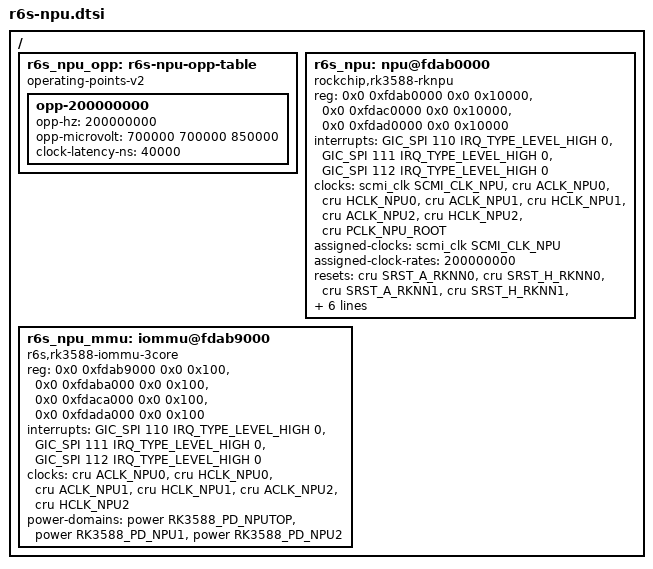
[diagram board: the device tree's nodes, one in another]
// SPDX-License-Identifier: (GPL-2.0+ OR MIT)
/* Modified 2026-10-11 for the R6S port; see docs/PORTING.md. */
/* R6S three-core mainline port. Register/IRQ/reset data are vendor0.9.8
 * and upstream v6.18 all three cores; initial SCMI rate is the upstream 200MHz.
 * The 700mV value is the vendor's ordinary 300/400MHz default voltage,
 * used here at the lower assigned rate. Hardware bring-up has been observed; full qualification remains incomplete. */
/ {
 r6s_npu_opp: r6s-npu-opp-table {
  compatible = "operating-points-v2";
  opp-200000000 {
   opp-hz = /bits/ 64 <200000000>;
   opp-microvolt = <700000 700000 850000>;
   clock-latency-ns = <40000>;
  };
 };
 r6s_npu: npu@fdab0000 {
  compatible = "rockchip,rk3588-rknpu";
  reg = <0x0 0xfdab0000 0x0 0x10000>,
        <0x0 0xfdac0000 0x0 0x10000>,
        <0x0 0xfdad0000 0x0 0x10000>;
  interrupts = <GIC_SPI 110 IRQ_TYPE_LEVEL_HIGH 0>,
               <GIC_SPI 111 IRQ_TYPE_LEVEL_HIGH 0>,
               <GIC_SPI 112 IRQ_TYPE_LEVEL_HIGH 0>;
  interrupt-names = "npu0_irq", "npu1_irq", "npu2_irq";
  clocks = <&scmi_clk SCMI_CLK_NPU>, <&cru ACLK_NPU0>,
           <&cru HCLK_NPU0>, <&cru ACLK_NPU1>, <&cru HCLK_NPU1>,
           <&cru ACLK_NPU2>, <&cru HCLK_NPU2>, <&cru PCLK_NPU_ROOT>;
  clock-names = "clk_npu", "aclk0", "hclk0", "aclk1", "hclk1", "aclk2", "hclk2", "pclk";
  assigned-clocks = <&scmi_clk SCMI_CLK_NPU>;
  assigned-clock-rates = <200000000>;
  resets = <&cru SRST_A_RKNN0>, <&cru SRST_H_RKNN0>,
           <&cru SRST_A_RKNN1>, <&cru SRST_H_RKNN1>,
           <&cru SRST_A_RKNN2>, <&cru SRST_H_RKNN2>;
  reset-names = "srst_a0", "srst_h0", "srst_a1", "srst_h1", "srst_a2", "srst_h2";
  power-domains = <&power RK3588_PD_NPUTOP>,
                  <&power RK3588_PD_NPU1>, <&power RK3588_PD_NPU2>;
  power-domain-names = "npu0", "npu1", "npu2";
  operating-points-v2 = <&r6s_npu_opp>;
  rknpu-supply = <&vdd_npu_s0>;
  iommus = <&r6s_npu_mmu>;
  status = "okay";
 };
 r6s_npu_mmu: iommu@fdab9000 {
  compatible = "r6s,rk3588-iommu-3core";
  reg = <0x0 0xfdab9000 0x0 0x100>,
        <0x0 0xfdaba000 0x0 0x100>,
        <0x0 0xfdaca000 0x0 0x100>,
        <0x0 0xfdada000 0x0 0x100>;
  interrupts = <GIC_SPI 110 IRQ_TYPE_LEVEL_HIGH 0>,
               <GIC_SPI 111 IRQ_TYPE_LEVEL_HIGH 0>,
               <GIC_SPI 112 IRQ_TYPE_LEVEL_HIGH 0>;
  clocks = <&cru ACLK_NPU0>, <&cru HCLK_NPU0>,
           <&cru ACLK_NPU1>, <&cru HCLK_NPU1>,
           <&cru ACLK_NPU2>, <&cru HCLK_NPU2>;
  clock-names = "aclk", "iface", "aclk1", "iface1", "aclk2", "iface2";
  #iommu-cells = <0>;
  power-domains = <&power RK3588_PD_NPUTOP>,
                  <&power RK3588_PD_NPU1>, <&power RK3588_PD_NPU2>;
  status = "okay";
 };
};
